# dm648_cslr_ddr2_001 register map
Vendor: Texas Instruments
Peripheral module from a debugger description file.
Registers are 32-bit, access not given, reset 0x31030F unless marked. A register's access mark holds for its fields unless they carry their own. Offsets are as the file gives them; lines under a group give offsets from that group; [hi:lo] are bit positions; {n}, {i} and the like mark numbered series; 'fields as' and 'values as' point back to an identical list; <NAME> marks a mode.

## DDR2_Memory_Controller
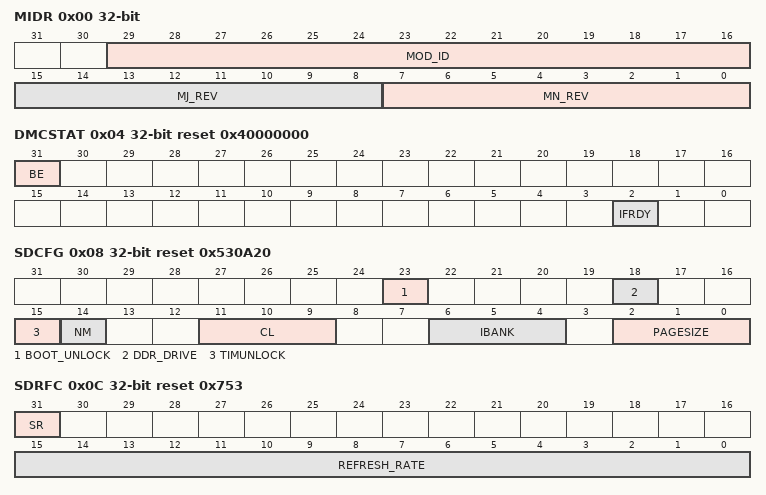
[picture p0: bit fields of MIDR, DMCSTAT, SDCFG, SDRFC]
0x00 MIDR — Module ID and Revision Register
  [29:16] MOD_ID ro — Module ID bits
  [15:8] MJ_REV ro — Major revision.
  [7:0] MN_REV ro — Minor revision.
0x04 DMCSTAT reset 0x40000000 — DDR2 Memory Controller Status Register
  [31] BE ro — Big endian bit.
  [2] IFRDY ro — DDR2 memory controller interface logic ready bit.
0x08 SDCFG reset 0x530A20 — SDRAM Configuration Register
  [23] BOOT_UNLOCK rw — Boot unlock bit.
  [18] DDR_DRIVE ro — DDR2 SDRAM drive strength.
  [15] TIMUNLOCK rw — Timing unlock bit.
  [14] NM rw — DDR2 data bus width.
  [11:9] CL rw — CAS latency.
  [6:4] IBANK rw — Internal SDRAM bank setup bits.
  [2:0] PAGESIZE rw — Page size bits.
0x0C SDRFC reset 0x753 — SDRAM Refresh Control Register
  [31] SR ro — Self-refresh bit
  [15:0] REFRESH_RATE rw — Refresh rate bits.
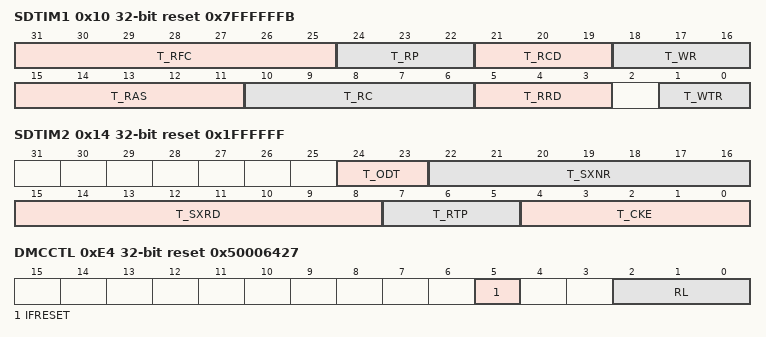
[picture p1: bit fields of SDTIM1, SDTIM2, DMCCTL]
0x10 SDTIM1 reset 0x7FFFFFFB — SDRAM Timing 1 Register
  [31:25] T_RFC rw — These bits specify the minimum number of DDR2CLKOUT cycles from a refresh or load mode command to a refresh or activate command, minus one.
  [24:22] T_RP rw — These bits specify the minimum number of DDR2CLKOUT cycles from a precharge command to a refresh or activate command, minus one.
  [21:19] T_RCD rw — These bits specify the minimum number of DDR2CLKOUT cylcles from an activate command to a read or write command, minus 1.
  [18:16] T_WR rw — These bits specify the minimum number of DDR2CLKOUT cylcles from the last write transfer to a precharge command, minus 1
  [15:11] T_RAS rw — These bits specify the minimum number of DDR2CLKOUT cylcles from an activate command to a precharge command, minus 1.
  [10:6] T_RC rw — These bits specify the minimum number of DDR2CLKOUT cylcles from an activate command to an activate command, minus 1.
  [5:3] T_RRD rw — These bits specify the minimum number of DDR2CLKOUT cylcles from an activate command to an activate command in a different bank, minus 1.
  [1:0] T_WTR rw — These bits specify the minimum number of DDR2CLKOUT cylcles from the last write transfer to a read command, minus 1.
0x14 SDTIM2 reset 0x1FFFFFF — SDRAM Timing 2 Register
  [24:23] T_ODT rw — These bits specify the minimum number of DDR2CLKOUT cylcles from ODT enable to write data driven for DDR2 SDRAM.
  [22:16] T_SXNR rw — These bits specify the minimum number of DDR2CLKOUT cylcles from a self_refresh exit to any other command except a read command, minus 1.
  [15:8] T_SXRD rw — These bits specify the minimum number of DDR2CLKOUT cylcles from a self_refresh exit to a read command, minus 1.
  [7:5] T_RTP rw — These bits specify the minimum number of DDR2CLKOUT cylcles from a last read command to a precharge command.
  [4:0] T_CKE rw — These bits specify the minimum number of DDR2CLKOUT cylcles between transitions on the DSDCKE pin, minus 1.
0x20 BPRIO reset 0xFF — Burst Priority Register
  [7:0] PRIO_RAISE rw — Number of memory transfers after which the DDR2 memory controller will elevate the priority of the oldest command in the command FIFO.
0xE4 DMCCTL reset 0x50006427 — DDR2 Memory Controller Control Register
  [5] IFRESET rw — DDR2 memory controller interface logic reset
  [2:0] RL rw — Read Latency bits.
